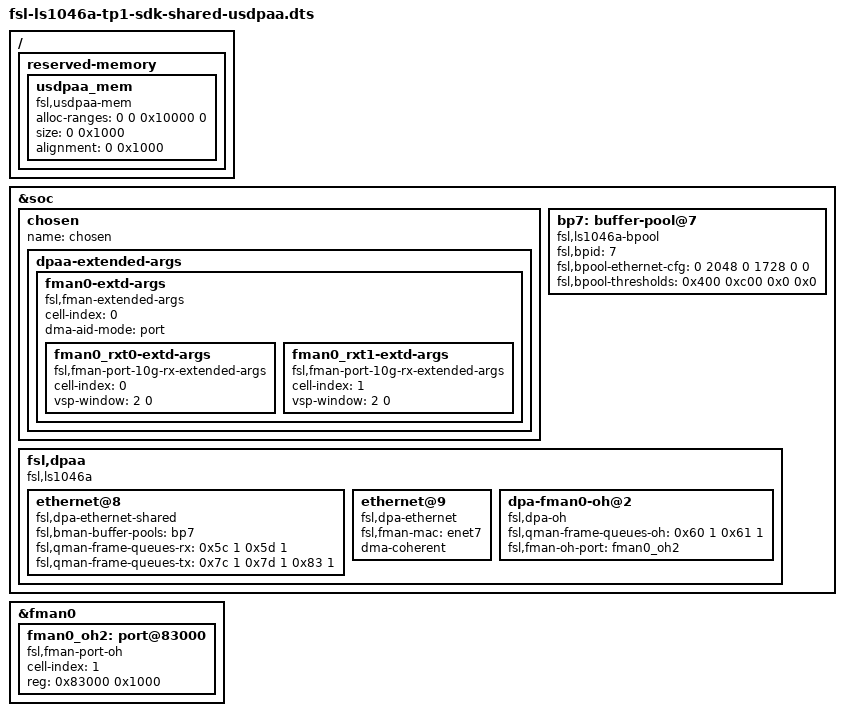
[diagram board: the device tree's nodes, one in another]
/*
 * Device Tree Include file for Freescale Layerscape-1046A family SoC.
 *
 * Copyright 2020-2022 NXP.
 *
 * This file is licensed under the terms of the GNU General Public
 * License version 2.  This program is licensed "as is" without any
 * warranty of any kind, whether express or implied.
 */

#include "fsl-ls1046a-tp1-sdk.dts"
&soc {
 	chosen {
 		name = "chosen";
 		dpaa-extended-args {
 			fman0-extd-args {
 
 				cell-index = <0>;
 				compatible = "fsl,fman-extended-args";
 				dma-aid-mode = "port";
 
 				fman0_rxt0-extd-args {
 					cell-index = <0>;
 					compatible = "fsl,fman-port-10g-rx-extended-args";
 					/* Define Virtual storage profile */
 					/* <number of profiles, default profile id */
 					vsp-window = <2 0>;
 				};
 
 				fman0_rxt1-extd-args {
 					cell-index = <1>;
 					compatible = "fsl,fman-port-10g-rx-extended-args";
 					/* Define Virtual storage profile */
 					/* <number of profiles, default profile id */
 					vsp-window = <2 0>;
 				};
 			};
 		};
	};
	bp7: buffer-pool@7 {
		compatible = "fsl,ls1046a-bpool", "fsl,bpool";
		fsl,bpid = <7>;
		fsl,bpool-ethernet-cfg = <0 2048 0 1728 0 0>;
		fsl,bpool-thresholds = <0x400 0xc00 0x0 0x0>;
	};

	fsl,dpaa {
		compatible = "fsl,ls1046a", "fsl,dpaa", "simple-bus";

		ethernet@8 {
			compatible = "fsl,dpa-ethernet-shared";
			fsl,bman-buffer-pools = <&bp7>;
			fsl,qman-frame-queues-rx = <0x5c 1 0x5d 1>;
			fsl,qman-frame-queues-tx = <0x7c 1 0x7d 1 0x83 1>;
		};

		ethernet@9 {
			compatible = "fsl,dpa-ethernet";
			fsl,fman-mac = <&enet7>;
			dma-coherent;
		};

		dpa-fman0-oh@2 {
			compatible = "fsl,dpa-oh";
			fsl,qman-frame-queues-oh = <0x60 1 0x61 1>;
			fsl,fman-oh-port = <&fman0_oh2>;
		};
	};
};
/ {
	reserved-memory {
		#address-cells = <2>;
		#size-cells = <2>;
		ranges;

		/* For legacy usdpaa based use-cases, update the size and
		alignment parameters. e.g. to allocate 256 MB memory:
                size = <0 0x10000000>;
                alignment = <0 0x10000000>;
                */
		usdpaa_mem: usdpaa_mem {
			compatible = "fsl,usdpaa-mem";
			alloc-ranges = <0 0 0x10000 0>;
			size = <0 0x1000>;
			alignment = <0 0x1000>;
		};
	};
};

&fman0 {
	fman0_oh2: port@83000 {
		cell-index = <1>;
		compatible = "fsl,fman-port-oh";
		reg = <0x83000 0x1000>;
	};
};
